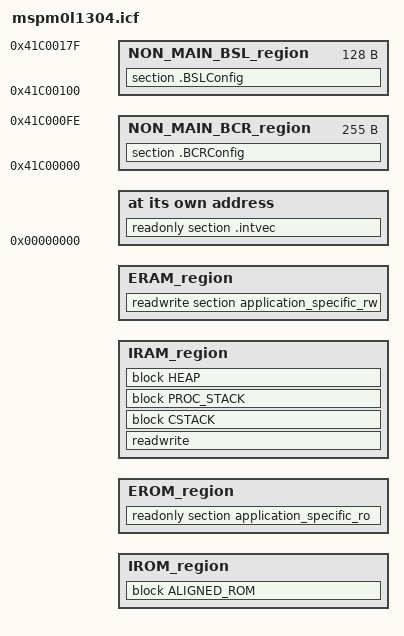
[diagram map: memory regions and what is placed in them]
/*****************************************************************************

  Copyright (C) 2024 Texas Instruments Incorporated - http://www.ti.com/ 

  Redistribution and use in source and binary forms, with or without 
  modification, are permitted provided that the following conditions 
  are met:

   Redistributions of source code must retain the above copyright 
   notice, this list of conditions and the following disclaimer.

   Redistributions in binary form must reproduce the above copyright
   notice, this list of conditions and the following disclaimer in the 
   documentation and/or other materials provided with the   
   distribution.

   Neither the name of Texas Instruments Incorporated nor the names of
   its contributors may be used to endorse or promote products derived
   from this software without specific prior written permission.

  THIS SOFTWARE IS PROVIDED BY THE COPYRIGHT HOLDERS AND CONTRIBUTORS 
  "AS IS" AND ANY EXPRESS OR IMPLIED WARRANTIES, INCLUDING, BUT NOT 
  LIMITED TO, THE IMPLIED WARRANTIES OF MERCHANTABILITY AND FITNESS FOR
  A PARTICULAR PURPOSE ARE DISCLAIMED. IN NO EVENT SHALL THE COPYRIGHT 
  OWNER OR CONTRIBUTORS BE LIABLE FOR ANY DIRECT, INDIRECT, INCIDENTAL, 
  SPECIAL, EXEMPLARY, OR CONSEQUENTIAL DAMAGES (INCLUDING, BUT NOT 
  LIMITED TO, PROCUREMENT OF SUBSTITUTE GOODS OR SERVICES; LOSS OF USE,
  DATA, OR PROFITS; OR BUSINESS INTERRUPTION) HOWEVER CAUSED AND ON ANY
  THEORY OF LIABILITY, WHETHER IN CONTRACT, STRICT LIABILITY, OR TORT 
  (INCLUDING NEGLIGENCE OR OTHERWISE) ARISING IN ANY WAY OUT OF THE USE 
  OF THIS SOFTWARE, EVEN IF ADVISED OF THE POSSIBILITY OF SUCH DAMAGE.

*****************************************************************************/
/*###ICF### Section handled by ICF editor, don't touch! ****/
/*-Editor annotation file-*/
/* IcfEditorFile="$TOOLKIT_DIR$\config\ide\IcfEditor\cortex_v1_4.xml" */
/*-Specials-*/
define symbol __ICFEDIT_intvec_start__ = 0x0000000;

/*-Memory Regions-*/
define symbol __ICFEDIT_region_IROM1_start__ = 0x00000000;
define symbol __ICFEDIT_region_IROM1_end__   = 0x00003FF7;
define symbol __ICFEDIT_region_IROM2_start__ = 0x0;
define symbol __ICFEDIT_region_IROM2_end__   = 0x0;
define symbol __ICFEDIT_region_EROM1_start__ = 0x0;
define symbol __ICFEDIT_region_EROM1_end__   = 0x0;
define symbol __ICFEDIT_region_EROM2_start__ = 0x0;
define symbol __ICFEDIT_region_EROM2_end__   = 0x0;
define symbol __ICFEDIT_region_EROM3_start__ = 0x0;
define symbol __ICFEDIT_region_EROM3_end__   = 0x0;
define symbol __ICFEDIT_region_IRAM1_start__ = 0x20000000;
define symbol __ICFEDIT_region_IRAM1_end__   = 0x200007FF;
define symbol __ICFEDIT_region_IRAM2_start__ = 0x0;
define symbol __ICFEDIT_region_IRAM2_end__   = 0x0;
define symbol __ICFEDIT_region_ERAM1_start__ = 0x0;
define symbol __ICFEDIT_region_ERAM1_end__   = 0x0;
define symbol __ICFEDIT_region_ERAM2_start__ = 0x0;
define symbol __ICFEDIT_region_ERAM2_end__   = 0x0;
define symbol __ICFEDIT_region_ERAM3_start__ = 0x0;
define symbol __ICFEDIT_region_ERAM3_end__   = 0x0;
define symbol __ICFEDIT_region_NON_MAIN_BCR_start__ = 0x41C00000;
define symbol __ICFEDIT_region_NON_MAIN_BCR_end__   = 0x41C000FE;
define symbol __ICFEDIT_region_NON_MAIN_BSL_start__ = 0x41C00100;
define symbol __ICFEDIT_region_NON_MAIN_BSL_end__   = 0x41C0017F;
/*-Sizes-*/
define symbol __ICFEDIT_size_proc_stack__ = 0x0000;
define symbol __ICFEDIT_size_cstack__     = 0x200;
define symbol __ICFEDIT_size_heap__       = 0x400;
/**** End of ICF editor section. ###ICF###*/

define memory mem with size = 4G;
define symbol use_IROM1 = (__ICFEDIT_region_IROM1_start__ != 0x0 || __ICFEDIT_region_IROM1_end__ != 0x0);
define symbol use_IROM2 = (__ICFEDIT_region_IROM2_start__ != 0x0 || __ICFEDIT_region_IROM2_end__ != 0x0);
define symbol use_EROM1 = (__ICFEDIT_region_EROM1_start__ != 0x0 || __ICFEDIT_region_EROM1_end__ != 0x0);
define symbol use_EROM2 = (__ICFEDIT_region_EROM2_start__ != 0x0 || __ICFEDIT_region_EROM2_end__ != 0x0);
define symbol use_EROM3 = (__ICFEDIT_region_EROM3_start__ != 0x0 || __ICFEDIT_region_EROM3_end__ != 0x0);
define symbol use_IRAM1 = (__ICFEDIT_region_IRAM1_start__ != 0x0 || __ICFEDIT_region_IRAM1_end__ != 0x0);
define symbol use_IRAM2 = (__ICFEDIT_region_IRAM2_start__ != 0x0 || __ICFEDIT_region_IRAM2_end__ != 0x0);
define symbol use_ERAM1 = (__ICFEDIT_region_ERAM1_start__ != 0x0 || __ICFEDIT_region_ERAM1_end__ != 0x0);
define symbol use_ERAM2 = (__ICFEDIT_region_ERAM2_start__ != 0x0 || __ICFEDIT_region_ERAM2_end__ != 0x0);
define symbol use_ERAM3 = (__ICFEDIT_region_ERAM3_start__ != 0x0 || __ICFEDIT_region_ERAM3_end__ != 0x0);

if (use_IROM1)
{
    define region IROM1_region = mem:[from __ICFEDIT_region_IROM1_start__ to __ICFEDIT_region_IROM1_end__];
}
else
{
    define region IROM1_region = [];
}

if (use_IROM2)
{
    define region IROM2_region = mem:[from __ICFEDIT_region_IROM2_start__ to __ICFEDIT_region_IROM2_end__];
}
else
{
    define region IROM2_region = [];
}
define region IROM_region = IROM1_region | IROM2_region;

if (use_EROM1)
{
    define region EROM1_region = mem:[from __ICFEDIT_region_EROM1_start__ to __ICFEDIT_region_EROM1_end__];
}
else
{
    define region EROM1_region = [];
}
if (use_EROM2)
{
    define region EROM2_region = mem:[from __ICFEDIT_region_EROM2_start__ to __ICFEDIT_region_EROM2_end__];
}
else
{
    define region EROM2_region = [];
}
if (use_EROM3)
{
    define region EROM3_region = mem:[from __ICFEDIT_region_EROM3_start__ to __ICFEDIT_region_EROM3_end__];
}
else
{
    define region EROM3_region = [];
}
define region EROM_region = EROM1_region | EROM2_region | EROM3_region;

if (use_IRAM1)
{
    define region IRAM1_region = mem:[from __ICFEDIT_region_IRAM1_start__ to __ICFEDIT_region_IRAM1_end__];
}
else
{
    define region IRAM1_region = [];
}
if (use_IRAM2)
{
    define region IRAM2_region = mem:[from __ICFEDIT_region_IRAM2_start__ to __ICFEDIT_region_IRAM2_end__];
}
else
{
    define region IRAM2_region = [];
}
define region IRAM_region = IRAM1_region | IRAM2_region;

if (use_ERAM1)
{
    define region ERAM1_region = mem:[from __ICFEDIT_region_ERAM1_start__ to __ICFEDIT_region_ERAM1_end__];
}
else
{
  define region ERAM1_region = [];
}
if (use_ERAM2)
{
    define region ERAM2_region = mem:[from __ICFEDIT_region_ERAM2_start__ to __ICFEDIT_region_ERAM2_end__];
}
else
{
    define region ERAM2_region = [];
}
if (use_ERAM3)
{
    define region ERAM3_region = mem:[from __ICFEDIT_region_ERAM3_start__ to __ICFEDIT_region_ERAM3_end__];
}
else
{
    define region ERAM3_region = [];
}
define region ERAM_region = ERAM1_region | ERAM2_region | ERAM3_region;

define region NON_MAIN_BCR_region = mem:[from __ICFEDIT_region_NON_MAIN_BCR_start__ to __ICFEDIT_region_NON_MAIN_BCR_end__];
define region NON_MAIN_BSL_region = mem:[from __ICFEDIT_region_NON_MAIN_BSL_start__ to __ICFEDIT_region_NON_MAIN_BSL_end__];

initialize by copy { readwrite };
do not initialize  { section .noinit };

place at address mem:__ICFEDIT_intvec_start__ { readonly section .intvec };

if (!isempty(IROM_region))
{
    // Create an 8-byte end-aligned block and put all read-only sections in it
    define block ALIGNED_ROM with end alignment = 8 { readonly };

    place in IROM_region  { block ALIGNED_ROM };
}

if (!isempty(EROM_region))
{
    place in EROM_region  { readonly section application_specific_ro };
}

if (!isempty(IRAM_region))
{
    define block CSTACK     with alignment = 8, size = __ICFEDIT_size_cstack__     { };
    define block PROC_STACK with alignment = 8, size = __ICFEDIT_size_proc_stack__ { };
    define block HEAP       with alignment = 8, size = __ICFEDIT_size_heap__       { };
    place in IRAM_region  { readwrite, block CSTACK, block PROC_STACK, block HEAP };
}

if (!isempty(ERAM_region))
{
    place in ERAM_region  { readwrite section application_specific_rw };
}

place in NON_MAIN_BCR_region  { section .BCRConfig };

place in NON_MAIN_BSL_region  { section .BSLConfig };

